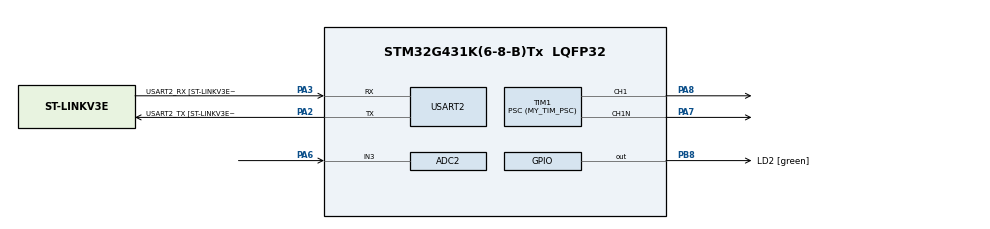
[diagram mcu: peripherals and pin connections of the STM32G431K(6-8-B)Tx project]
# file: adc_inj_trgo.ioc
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ADC2.ClockPrescaler=ADC_CLOCK_ASYNC_DIV4
ADC2.EnableInjectedConversion=ENABLE
ADC2.EnableRegularConversion=DISABLE
ADC2.ExternalTrigInjecConv=ADC_EXTERNALTRIGINJEC_T1_TRGO
ADC2.ExternalTrigInjecConvEdge=ADC_EXTERNALTRIGINJECCONV_EDGE_FALLING
ADC2.InjNumberOfConversion=1
ADC2.InjectedChannel-1\#ChannelInjectedConversion=ADC_CHANNEL_3
ADC2.InjectedOffsetNumber-1\#ChannelInjectedConversion=ADC_OFFSET_NONE
ADC2.InjectedRank-1\#ChannelInjectedConversion=1
ADC2.InjectedSamplingTime-1\#ChannelInjectedConversion=ADC_SAMPLETIME_6CYCLES_5
ADC2.Rank1_Channel=ADC_CHANNEL_3
Mcu.Family=STM32G4
Mcu.Name=STM32G431K(6-8-B)Tx
Mcu.Package=LQFP32
NVIC.ADC1_2_IRQn=true\:0\:0\:false\:false\:true\:true\:true\:true
NVIC.PriorityGroup=NVIC_PRIORITYGROUP_4
PA13.GPIO_Label=T_SWDIO
PA13.Mode=Serial_Wire
PA13.Signal=SYS_JTMS-SWDIO
PA14.GPIO_Label=T_SWCLK
PA14.Mode=Serial_Wire
PA14.Signal=SYS_JTCK-SWCLK
PA2.GPIO_Label=USART2_TX [ST-LINKV3E_VCP_RX]
PA2.Mode=Asynchronous
PA2.Signal=USART2_TX
PA3.GPIO_Label=USART2_RX [ST-LINKV3E_VCP_TX]
PA3.Mode=Asynchronous
PA3.Signal=USART2_RX
PA6.Mode=IN3-Single-Ended
PA6.Signal=ADC2_IN3
PA7.Mode=PWM Generation1 CH1 CH1N
PA7.Signal=TIM1_CH1N
PA8.Signal=S_TIM1_CH1
PB3.GPIO_Label=T_SWO
PB3.Signal=SYS_JTDO-SWO
PB8-BOOT0.GPIO_Label=LD2 [green]
PB8-BOOT0.Signal=GPIO_Output
ProjectManager.HeapSize=0x200
ProjectManager.StackSize=0x400
ProjectManager.TargetToolchain=STM32CubeIDE
RCC.ADC12Freq_Value=170000000
RCC.AHBFreq_Value=170000000
RCC.APB1Freq_Value=170000000
RCC.APB1TimFreq_Value=170000000
RCC.APB2Freq_Value=170000000
RCC.APB2TimFreq_Value=170000000
RCC.CortexFreq_Value=170000000
RCC.EXTERNAL_CLOCK_VALUE=12288000
RCC.HCLKFreq_Value=170000000
RCC.HSE_VALUE=8000000
RCC.HSI48_VALUE=48000000
RCC.HSI_VALUE=16000000
RCC.LSE_VALUE=32768
RCC.PLLM=RCC_PLLM_DIV4
RCC.PLLN=85
RCC.SYSCLKFreq_VALUE=170000000
RCC.SYSCLKSource=RCC_SYSCLKSOURCE_PLLCLK
RCC.USBFreq_Value=170000000
RCC.VCOOutputFreq_Value=340000000
SH.S_TIM1_CH1.0=TIM1_CH1,PWM Generation1 CH1 CH1N
TIM1.Channel-PWM\ Generation1\ CH1\ CH1N=TIM_CHANNEL_1
TIM1.Channel-PWM\ Generation4\ No\ Output=TIM_CHANNEL_4
TIM1.CounterMode=TIM_COUNTERMODE_CENTERALIGNED1
TIM1.OCMode_PWM-PWM\ Generation4\ No\ Output=TIM_OCMODE_PWM2
TIM1.PeriodNoDither=(MY_TIM_ARR)
TIM1.Prescaler=(MY_TIM_PSC)
TIM1.PulseNoDither_1=((MY_TIM_ARR+1) * 0.5F)
TIM1.PulseNoDither_4=1
TIM1.TIM_MasterOutputTrigger=TIM_TRGO_OC4REF
TIM1.TIM_MasterOutputTrigger2=TIM_TRGO2_UPDATE
USART2.BaudRate=(MY_UART_BAUDRATE)
USART2.VirtualMode-Asynchronous=VM_ASYNC
USART2.WordLength=WORDLENGTH_8B
VP_SYS_VS_DBSignals.Mode=DisableDeadBatterySignals
VP_TIM1_VS_ClockSourceINT.Mode=Internal
VP_TIM1_VS_no_output4.Mode=PWM Generation4 No Output
board=NUCLEO-G431KB

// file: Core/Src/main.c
/* USER CODE BEGIN Header */
/**
  ******************************************************************************
  * @file           : main.c
  * @brief          : Main program body
  ******************************************************************************
  * @attention
  *
  * Copyright (c) 2024 STMicroelectronics.
  * All rights reserved.
  *
  * This software is licensed under terms that can be found in the LICENSE file
  * in the root directory of this software component.
  * If no LICENSE file comes with this software, it is provided AS-IS.
  *
  ******************************************************************************
  */
/* USER CODE END Header */
#include "main.h"

/* USER CODE BEGIN Includes */
#include "../../User/user_main.h"
/* USER CODE END Includes */

void SystemClock_Config(void);
static void MX_GPIO_Init(void);
static void MX_ADC2_Init(void);
static void MX_TIM1_Init(void);
static void MX_USART2_UART_Init(void);

int main(void)
{

  /* MCU Configuration--------------------------------------------------------*/

  /* Reset of all peripherals, Initializes the Flash interface and the Systick. */
  LL_APB2_GRP1_EnableClock(LL_APB2_GRP1_PERIPH_SYSCFG);
  LL_APB1_GRP1_EnableClock(LL_APB1_GRP1_PERIPH_PWR);

  /* System interrupt init*/
  NVIC_SetPriorityGrouping(NVIC_PRIORITYGROUP_4);

  /** Disable the internal Pull-Up in Dead Battery pins of UCPD peripheral
  */
  LL_PWR_DisableUCPDDeadBattery();

  /* Configure the system clock */
  SystemClock_Config();

  /* Initialize all configured peripherals */
  MX_GPIO_Init();
  MX_ADC2_Init();
  MX_TIM1_Init();
  MX_USART2_UART_Init();
  /* USER CODE BEGIN 2 */
  User_Init();
  /* USER CODE END 2 */

  /* Infinite loop */
  /* USER CODE BEGIN WHILE */
  while (1)
  {
    User_Loop();
    /* USER CODE END WHILE */

  }
}

void SystemClock_Config(void)
{
  LL_FLASH_SetLatency(LL_FLASH_LATENCY_4);
  while(LL_FLASH_GetLatency() != LL_FLASH_LATENCY_4)
  {
  }
  LL_PWR_EnableRange1BoostMode();
  LL_RCC_HSI_Enable();
   /* Wait till HSI is ready */
  while(LL_RCC_HSI_IsReady() != 1)
  {
  }

  LL_RCC_HSI_SetCalibTrimming(64);
  LL_RCC_PLL_ConfigDomain_SYS(LL_RCC_PLLSOURCE_HSI, LL_RCC_PLLM_DIV_4, 85, LL_RCC_PLLR_DIV_2);
  LL_RCC_PLL_EnableDomain_SYS();
  LL_RCC_PLL_Enable();
   /* Wait till PLL is ready */
  while(LL_RCC_PLL_IsReady() != 1)
  {
  }

  LL_RCC_SetSysClkSource(LL_RCC_SYS_CLKSOURCE_PLL);
  LL_RCC_SetAHBPrescaler(LL_RCC_SYSCLK_DIV_2);
   /* Wait till System clock is ready */
  while(LL_RCC_GetSysClkSource() != LL_RCC_SYS_CLKSOURCE_STATUS_PLL)
  {
  }

  /* Insure 1us transition state at intermediate medium speed clock*/
  for (__IO uint32_t i = (170 >> 1); i !=0; i--);

  /* Set AHB prescaler*/
  LL_RCC_SetAHBPrescaler(LL_RCC_SYSCLK_DIV_1);
  LL_RCC_SetAPB1Prescaler(LL_RCC_APB1_DIV_1);
  LL_RCC_SetAPB2Prescaler(LL_RCC_APB2_DIV_1);

  LL_Init1msTick(170000000);

  LL_SetSystemCoreClock(170000000);
}

static void MX_ADC2_Init(void)
{

  LL_ADC_InitTypeDef ADC_InitStruct = {0};
  LL_ADC_REG_InitTypeDef ADC_REG_InitStruct = {0};
  LL_ADC_CommonInitTypeDef ADC_CommonInitStruct = {0};
  LL_ADC_INJ_InitTypeDef ADC_INJ_InitStruct = {0};

  LL_GPIO_InitTypeDef GPIO_InitStruct = {0};

  LL_RCC_SetADCClockSource(LL_RCC_ADC12_CLKSOURCE_SYSCLK);

  /* Peripheral clock enable */
  LL_AHB2_GRP1_EnableClock(LL_AHB2_GRP1_PERIPH_ADC12);

  LL_AHB2_GRP1_EnableClock(LL_AHB2_GRP1_PERIPH_GPIOA);
  /**ADC2 GPIO Configuration
  PA6   ------> ADC2_IN3
  */
  GPIO_InitStruct.Pin = LL_GPIO_PIN_6;
  GPIO_InitStruct.Mode = LL_GPIO_MODE_ANALOG;
  GPIO_InitStruct.Pull = LL_GPIO_PULL_NO;
  LL_GPIO_Init(GPIOA, &GPIO_InitStruct);

  /* ADC2 interrupt Init */
  NVIC_SetPriority(ADC1_2_IRQn, NVIC_EncodePriority(NVIC_GetPriorityGrouping(),0, 0));
  NVIC_EnableIRQ(ADC1_2_IRQn);

  /** Common config
  */
  ADC_InitStruct.Resolution = LL_ADC_RESOLUTION_12B;
  ADC_InitStruct.DataAlignment = LL_ADC_DATA_ALIGN_RIGHT;
  ADC_InitStruct.LowPowerMode = LL_ADC_LP_MODE_NONE;
  LL_ADC_Init(ADC2, &ADC_InitStruct);
  ADC_REG_InitStruct.SequencerLength = LL_ADC_REG_SEQ_SCAN_DISABLE;
  ADC_REG_InitStruct.SequencerDiscont = LL_ADC_REG_SEQ_DISCONT_DISABLE;
  ADC_REG_InitStruct.ContinuousMode = LL_ADC_REG_CONV_SINGLE;
  ADC_REG_InitStruct.DMATransfer = LL_ADC_REG_DMA_TRANSFER_NONE;
  ADC_REG_InitStruct.Overrun = LL_ADC_REG_OVR_DATA_PRESERVED;
  LL_ADC_REG_Init(ADC2, &ADC_REG_InitStruct);
  LL_ADC_SetGainCompensation(ADC2, 0);
  LL_ADC_SetOverSamplingScope(ADC2, LL_ADC_OVS_DISABLE);
  ADC_CommonInitStruct.CommonClock = LL_ADC_CLOCK_ASYNC_DIV4;
  LL_ADC_CommonInit(__LL_ADC_COMMON_INSTANCE(ADC2), &ADC_CommonInitStruct);
  ADC_INJ_InitStruct.TriggerSource = LL_ADC_INJ_TRIG_EXT_TIM1_TRGO;
  ADC_INJ_InitStruct.SequencerLength = LL_ADC_INJ_SEQ_SCAN_DISABLE;
  ADC_INJ_InitStruct.SequencerDiscont = LL_ADC_INJ_SEQ_DISCONT_DISABLE;
  ADC_INJ_InitStruct.TrigAuto = LL_ADC_INJ_TRIG_INDEPENDENT;
  LL_ADC_INJ_Init(ADC2, &ADC_INJ_InitStruct);
  LL_ADC_INJ_SetQueueMode(ADC2, LL_ADC_INJ_QUEUE_DISABLE);
  LL_ADC_INJ_SetTriggerEdge(ADC2, LL_ADC_INJ_TRIG_EXT_FALLING);

  /* Disable ADC deep power down (enabled by default after reset state) */
  LL_ADC_DisableDeepPowerDown(ADC2);
  /* Enable ADC internal voltage regulator */
  LL_ADC_EnableInternalRegulator(ADC2);
  /* Delay for ADC internal voltage regulator stabilization. */
  /* Compute number of CPU cycles to wait for, from delay in us. */
  /* Note: Variable divided by 2 to compensate partially */
  /* CPU processing cycles (depends on compilation optimization). */
  /* Note: If system core clock frequency is below 200kHz, wait time */
  /* is only a few CPU processing cycles. */
  uint32_t wait_loop_index;
  wait_loop_index = ((LL_ADC_DELAY_INTERNAL_REGUL_STAB_US * (SystemCoreClock / (100000 * 2))) / 10);
  while(wait_loop_index != 0)
  {
    wait_loop_index--;
  }

  /** Configure Injected Channel
  */
  LL_ADC_INJ_SetSequencerRanks(ADC2, LL_ADC_INJ_RANK_1, LL_ADC_CHANNEL_3);
  LL_ADC_SetChannelSamplingTime(ADC2, LL_ADC_CHANNEL_3, LL_ADC_SAMPLINGTIME_6CYCLES_5);
  LL_ADC_SetChannelSingleDiff(ADC2, LL_ADC_CHANNEL_3, LL_ADC_SINGLE_ENDED);

}

static void MX_TIM1_Init(void)
{

  LL_TIM_InitTypeDef TIM_InitStruct = {0};
  LL_TIM_OC_InitTypeDef TIM_OC_InitStruct = {0};
  LL_TIM_BDTR_InitTypeDef TIM_BDTRInitStruct = {0};

  LL_GPIO_InitTypeDef GPIO_InitStruct = {0};

  /* Peripheral clock enable */
  LL_APB2_GRP1_EnableClock(LL_APB2_GRP1_PERIPH_TIM1);

  TIM_InitStruct.Prescaler = (MY_TIM_PSC);
  TIM_InitStruct.CounterMode = LL_TIM_COUNTERMODE_CENTER_DOWN;
  TIM_InitStruct.Autoreload = (MY_TIM_ARR);
  TIM_InitStruct.ClockDivision = LL_TIM_CLOCKDIVISION_DIV1;
  TIM_InitStruct.RepetitionCounter = 0;
  LL_TIM_Init(TIM1, &TIM_InitStruct);
  LL_TIM_DisableARRPreload(TIM1);
  LL_TIM_SetClockSource(TIM1, LL_TIM_CLOCKSOURCE_INTERNAL);
  LL_TIM_OC_EnablePreload(TIM1, LL_TIM_CHANNEL_CH1);
  TIM_OC_InitStruct.OCMode = LL_TIM_OCMODE_PWM1;
  TIM_OC_InitStruct.OCState = LL_TIM_OCSTATE_DISABLE;
  TIM_OC_InitStruct.OCNState = LL_TIM_OCSTATE_DISABLE;
  TIM_OC_InitStruct.CompareValue = ((MY_TIM_ARR+1) * 0.5F);
  TIM_OC_InitStruct.OCPolarity = LL_TIM_OCPOLARITY_HIGH;
  TIM_OC_InitStruct.OCNPolarity = LL_TIM_OCPOLARITY_HIGH;
  TIM_OC_InitStruct.OCIdleState = LL_TIM_OCIDLESTATE_LOW;
  TIM_OC_InitStruct.OCNIdleState = LL_TIM_OCIDLESTATE_LOW;
  LL_TIM_OC_Init(TIM1, LL_TIM_CHANNEL_CH1, &TIM_OC_InitStruct);
  LL_TIM_OC_DisableFast(TIM1, LL_TIM_CHANNEL_CH1);
  LL_TIM_OC_EnablePreload(TIM1, LL_TIM_CHANNEL_CH4);
  TIM_OC_InitStruct.OCMode = LL_TIM_OCMODE_PWM2;
  TIM_OC_InitStruct.CompareValue = 1;
  LL_TIM_OC_Init(TIM1, LL_TIM_CHANNEL_CH4, &TIM_OC_InitStruct);
  LL_TIM_OC_DisableFast(TIM1, LL_TIM_CHANNEL_CH4);
  LL_TIM_SetTriggerOutput(TIM1, LL_TIM_TRGO_OC4REF);
  LL_TIM_SetTriggerOutput2(TIM1, LL_TIM_TRGO2_UPDATE);
  LL_TIM_DisableMasterSlaveMode(TIM1);
  TIM_BDTRInitStruct.OSSRState = LL_TIM_OSSR_DISABLE;
  TIM_BDTRInitStruct.OSSIState = LL_TIM_OSSI_DISABLE;
  TIM_BDTRInitStruct.LockLevel = LL_TIM_LOCKLEVEL_OFF;
  TIM_BDTRInitStruct.DeadTime = 0;
  TIM_BDTRInitStruct.BreakState = LL_TIM_BREAK_DISABLE;
  TIM_BDTRInitStruct.BreakPolarity = LL_TIM_BREAK_POLARITY_HIGH;
  TIM_BDTRInitStruct.BreakFilter = LL_TIM_BREAK_FILTER_FDIV1;
  TIM_BDTRInitStruct.BreakAFMode = LL_TIM_BREAK_AFMODE_INPUT;
  TIM_BDTRInitStruct.Break2State = LL_TIM_BREAK2_DISABLE;
  TIM_BDTRInitStruct.Break2Polarity = LL_TIM_BREAK2_POLARITY_HIGH;
  TIM_BDTRInitStruct.Break2Filter = LL_TIM_BREAK2_FILTER_FDIV1;
  TIM_BDTRInitStruct.Break2AFMode = LL_TIM_BREAK_AFMODE_INPUT;
  TIM_BDTRInitStruct.AutomaticOutput = LL_TIM_AUTOMATICOUTPUT_DISABLE;
  LL_TIM_BDTR_Init(TIM1, &TIM_BDTRInitStruct);
  LL_AHB2_GRP1_EnableClock(LL_AHB2_GRP1_PERIPH_GPIOA);
  /**TIM1 GPIO Configuration
  PA7   ------> TIM1_CH1N
  PA8   ------> TIM1_CH1
  */
  GPIO_InitStruct.Pin = LL_GPIO_PIN_7;
  GPIO_InitStruct.Mode = LL_GPIO_MODE_ALTERNATE;
  GPIO_InitStruct.Speed = LL_GPIO_SPEED_FREQ_LOW;
  GPIO_InitStruct.OutputType = LL_GPIO_OUTPUT_PUSHPULL;
  GPIO_InitStruct.Pull = LL_GPIO_PULL_NO;
  GPIO_InitStruct.Alternate = LL_GPIO_AF_6;
  LL_GPIO_Init(GPIOA, &GPIO_InitStruct);

  GPIO_InitStruct.Pin = LL_GPIO_PIN_8;
  GPIO_InitStruct.Mode = LL_GPIO_MODE_ALTERNATE;
  GPIO_InitStruct.Speed = LL_GPIO_SPEED_FREQ_LOW;
  GPIO_InitStruct.OutputType = LL_GPIO_OUTPUT_PUSHPULL;
  GPIO_InitStruct.Pull = LL_GPIO_PULL_NO;
  GPIO_InitStruct.Alternate = LL_GPIO_AF_6;
  LL_GPIO_Init(GPIOA, &GPIO_InitStruct);

}

static void MX_USART2_UART_Init(void)
{

  LL_USART_InitTypeDef USART_InitStruct = {0};

  LL_GPIO_InitTypeDef GPIO_InitStruct = {0};

  LL_RCC_SetUSARTClockSource(LL_RCC_USART2_CLKSOURCE_PCLK1);

  /* Peripheral clock enable */
  LL_APB1_GRP1_EnableClock(LL_APB1_GRP1_PERIPH_USART2);

  LL_AHB2_GRP1_EnableClock(LL_AHB2_GRP1_PERIPH_GPIOA);
  /**USART2 GPIO Configuration
  PA2   ------> USART2_TX
  PA3   ------> USART2_RX
  */
  GPIO_InitStruct.Pin = USART2_TX_Pin;
  GPIO_InitStruct.Mode = LL_GPIO_MODE_ALTERNATE;
  GPIO_InitStruct.Speed = LL_GPIO_SPEED_FREQ_LOW;
  GPIO_InitStruct.OutputType = LL_GPIO_OUTPUT_PUSHPULL;
  GPIO_InitStruct.Pull = LL_GPIO_PULL_NO;
  GPIO_InitStruct.Alternate = LL_GPIO_AF_7;
  LL_GPIO_Init(USART2_TX_GPIO_Port, &GPIO_InitStruct);

  GPIO_InitStruct.Pin = USART2_RX_Pin;
  GPIO_InitStruct.Mode = LL_GPIO_MODE_ALTERNATE;
  GPIO_InitStruct.Speed = LL_GPIO_SPEED_FREQ_LOW;
  GPIO_InitStruct.OutputType = LL_GPIO_OUTPUT_PUSHPULL;
  GPIO_InitStruct.Pull = LL_GPIO_PULL_NO;
  GPIO_InitStruct.Alternate = LL_GPIO_AF_7;
  LL_GPIO_Init(USART2_RX_GPIO_Port, &GPIO_InitStruct);

  USART_InitStruct.PrescalerValue = LL_USART_PRESCALER_DIV1;
  USART_InitStruct.BaudRate = (MY_UART_BAUDRATE);
  USART_InitStruct.DataWidth = LL_USART_DATAWIDTH_8B;
  USART_InitStruct.StopBits = LL_USART_STOPBITS_1;
  USART_InitStruct.Parity = LL_USART_PARITY_NONE;
  USART_InitStruct.TransferDirection = LL_USART_DIRECTION_TX_RX;
  USART_InitStruct.HardwareFlowControl = LL_USART_HWCONTROL_NONE;
  USART_InitStruct.OverSampling = LL_USART_OVERSAMPLING_16;
  LL_USART_Init(USART2, &USART_InitStruct);
  LL_USART_SetTXFIFOThreshold(USART2, LL_USART_FIFOTHRESHOLD_1_8);
  LL_USART_SetRXFIFOThreshold(USART2, LL_USART_FIFOTHRESHOLD_1_8);
  LL_USART_DisableFIFO(USART2);
  LL_USART_ConfigAsyncMode(USART2);

  LL_USART_Enable(USART2);

  /* Polling USART2 initialisation */
  while((!(LL_USART_IsActiveFlag_TEACK(USART2))) || (!(LL_USART_IsActiveFlag_REACK(USART2))))
  {
  }

}

static void MX_GPIO_Init(void)
{
  LL_GPIO_InitTypeDef GPIO_InitStruct = {0};

  /* GPIO Ports Clock Enable */
  LL_AHB2_GRP1_EnableClock(LL_AHB2_GRP1_PERIPH_GPIOA);
  LL_AHB2_GRP1_EnableClock(LL_AHB2_GRP1_PERIPH_GPIOB);

  /**/
  LL_GPIO_ResetOutputPin(LD2_GPIO_Port, LD2_Pin);

  /**/
  GPIO_InitStruct.Pin = LD2_Pin;
  GPIO_InitStruct.Mode = LL_GPIO_MODE_OUTPUT;
  GPIO_InitStruct.Speed = LL_GPIO_SPEED_FREQ_LOW;
  GPIO_InitStruct.OutputType = LL_GPIO_OUTPUT_PUSHPULL;
  GPIO_InitStruct.Pull = LL_GPIO_PULL_NO;
  LL_GPIO_Init(LD2_GPIO_Port, &GPIO_InitStruct);

}

void Error_Handler(void)
{
  __disable_irq();
  while (1)
  {
  }
}
